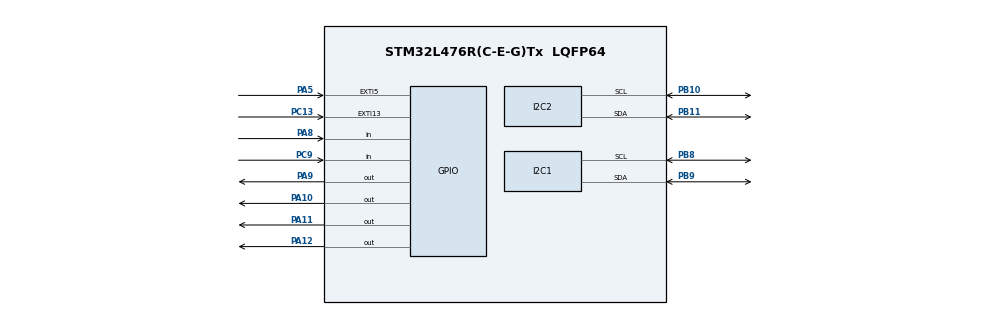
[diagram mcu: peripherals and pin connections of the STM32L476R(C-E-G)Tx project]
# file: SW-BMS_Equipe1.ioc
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Mcu.Family=STM32L4
Mcu.Name=STM32L476R(C-E-G)Tx
Mcu.Package=LQFP64
NVIC.PriorityGroup=NVIC_PRIORITYGROUP_4
PA10.Signal=GPIO_Output
PA11.Signal=GPIO_Output
PA12.Signal=GPIO_Output
PA13\ (JTMS-SWDIO).Signal=SYS_JTMS-SWDIO
PA14\ (JTCK-SWCLK).Signal=SYS_JTCK-SWCLK
PA2.Signal=USART2_TX
PA3.Signal=USART2_RX
PA5.Signal=GPXTI5
PA8.Signal=GPIO_Input
PA9.Signal=GPIO_Output
PB10.Mode=I2C
PB10.Signal=I2C2_SCL
PB11.Mode=I2C
PB11.Signal=I2C2_SDA
PB3\ (JTDO-TRACESWO).Signal=SYS_JTDO-SWO
PB8.Mode=I2C
PB8.Signal=I2C1_SCL
PB9.Mode=I2C
PB9.Signal=I2C1_SDA
PC13.Signal=GPXTI13
PC14-OSC32_IN\ (PC14).Mode=LSE-External-Oscillator
PC14-OSC32_IN\ (PC14).Signal=RCC_OSC32_IN
PC15-OSC32_OUT\ (PC15).Mode=LSE-External-Oscillator
PC15-OSC32_OUT\ (PC15).Signal=RCC_OSC32_OUT
PC9.Signal=GPIO_Input
PH0-OSC_IN\ (PH0).Mode=HSE-External-Oscillator
PH0-OSC_IN\ (PH0).Signal=RCC_OSC_IN
PH1-OSC_OUT\ (PH1).Mode=HSE-External-Oscillator
PH1-OSC_OUT\ (PH1).Signal=RCC_OSC_OUT
ProjectManager.HeapSize=0x200
ProjectManager.StackSize=0x400
ProjectManager.TargetToolchain=STM32CubeIDE
RCC.HSE_VALUE=8000000
RCC.HSI_VALUE=16000000
RCC.MSI_VALUE=4000000
RCC.VCOOutputFreq_Value=32000000
TIM6.Period=0xffff
TIM6.Prescaler=3999
VP_TIM6_VS_ClockSourceINT.Mode=Enable_Timer
board=custom

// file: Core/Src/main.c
/* USER CODE BEGIN Header */
/**
  ******************************************************************************
  * @file           : main.c
  * @brief          : Main program body
  ******************************************************************************
  * @attention
  *
  * <h2><center>&copy; Copyright (c) 2020 STMicroelectronics.
  * All rights reserved.</center></h2>
  *
  * This software component is licensed by ST under BSD 3-Clause license,
  * the "License"; You may not use this file except in compliance with the
  * License. You may obtain a copy of the License at:
  *                        opensource.org/licenses/BSD-3-Clause
  *
  ******************************************************************************
  */

/* USER CODE END Header */
#include "main.h"
#include "i2c.h"
#include "tim.h"
#include "gpio.h"

/* USER CODE BEGIN Includes */
#include "BMS_Management.h"
#include "InfoBatt.h"
#include "ModeBatt.h"
/* USER CODE END Includes */

void SystemClock_Config(void);

int main(void)
{

  /* MCU Configuration--------------------------------------------------------*/

  /* Reset of all peripherals, Initializes the Flash interface and the Systick. */
  HAL_Init();

  /* Configure the system clock */
  SystemClock_Config();

  /* Initialize all configured peripherals */
  MX_GPIO_Init();
  MX_I2C1_Init();
  MX_I2C2_Init();
  MX_TIM6_Init();
  /* USER CODE BEGIN 2 */
  BMSManagement_Init();
  /* USER CODE END 2 */

  /* Infinite loop */
  while (1)
  {

  }
}

void SystemClock_Config(void)
{
  RCC_OscInitTypeDef RCC_OscInitStruct = {0};
  RCC_ClkInitTypeDef RCC_ClkInitStruct = {0};
  RCC_PeriphCLKInitTypeDef PeriphClkInit = {0};

  /** Configure LSE Drive Capability
  */
  HAL_PWR_EnableBkUpAccess();
  __HAL_RCC_LSEDRIVE_CONFIG(RCC_LSEDRIVE_LOW);
  /** Initializes the RCC Oscillators according to the specified parameters
  * in the RCC_OscInitTypeDef structure.
  */
  RCC_OscInitStruct.OscillatorType = RCC_OSCILLATORTYPE_LSE|RCC_OSCILLATORTYPE_MSI;
  RCC_OscInitStruct.LSEState = RCC_LSE_ON;
  RCC_OscInitStruct.MSIState = RCC_MSI_ON;
  RCC_OscInitStruct.MSICalibrationValue = 0;
  RCC_OscInitStruct.MSIClockRange = RCC_MSIRANGE_6;
  RCC_OscInitStruct.PLL.PLLState = RCC_PLL_NONE;
  if (HAL_RCC_OscConfig(&RCC_OscInitStruct) != HAL_OK)
  {
    Error_Handler();
  }
  /** Initializes the CPU, AHB and APB buses clocks
  */
  RCC_ClkInitStruct.ClockType = RCC_CLOCKTYPE_HCLK|RCC_CLOCKTYPE_SYSCLK
                              |RCC_CLOCKTYPE_PCLK1|RCC_CLOCKTYPE_PCLK2;
  RCC_ClkInitStruct.SYSCLKSource = RCC_SYSCLKSOURCE_MSI;
  RCC_ClkInitStruct.AHBCLKDivider = RCC_SYSCLK_DIV1;
  RCC_ClkInitStruct.APB1CLKDivider = RCC_HCLK_DIV1;
  RCC_ClkInitStruct.APB2CLKDivider = RCC_HCLK_DIV1;

  if (HAL_RCC_ClockConfig(&RCC_ClkInitStruct, FLASH_LATENCY_0) != HAL_OK)
  {
    Error_Handler();
  }
  PeriphClkInit.PeriphClockSelection = RCC_PERIPHCLK_I2C1|RCC_PERIPHCLK_I2C2;
  PeriphClkInit.I2c1ClockSelection = RCC_I2C1CLKSOURCE_PCLK1;
  PeriphClkInit.I2c2ClockSelection = RCC_I2C2CLKSOURCE_PCLK1;
  if (HAL_RCCEx_PeriphCLKConfig(&PeriphClkInit) != HAL_OK)
  {
    Error_Handler();
  }
  /** Configure the main internal regulator output voltage
  */
  if (HAL_PWREx_ControlVoltageScaling(PWR_REGULATOR_VOLTAGE_SCALE1) != HAL_OK)
  {
    Error_Handler();
  }
  /** Enable MSI Auto calibration
  */
  HAL_RCCEx_EnableMSIPLLMode();
}

void Error_Handler(void)
{
}

/************************ (C) COPYRIGHT STMicroelectronics *****END OF FILE****/
